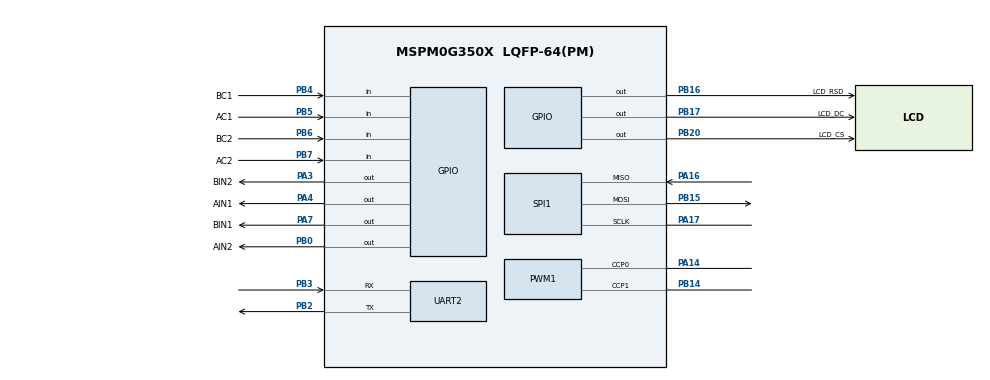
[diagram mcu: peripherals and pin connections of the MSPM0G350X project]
/**
 * @cliArgs --device "MSPM0G350X" --package "LQFP-64(PM)" --part "Default" --product "mspm0_sdk@1.30.00.03"
 * @versions {"tool":"1.19.0+3426"}
 */

/**
 * Import the modules used in this configuration.
 */
const GPIO    = scripting.addModule("/ti/driverlib/GPIO", {}, false);
const GPIO1   = GPIO.addInstance();
const GPIO2   = GPIO.addInstance();
const GPIO3   = GPIO.addInstance();
const GPIO4   = GPIO.addInstance();
const GPIO5   = GPIO.addInstance();
const GPIO6   = GPIO.addInstance();
const GPIO7   = GPIO.addInstance();
const GPIO8   = GPIO.addInstance();
const I2C     = scripting.addModule("/ti/driverlib/I2C", {}, false);
const I2C1    = I2C.addInstance();
const PWM     = scripting.addModule("/ti/driverlib/PWM", {}, false);
const PWM1    = PWM.addInstance();
const SPI     = scripting.addModule("/ti/driverlib/SPI", {}, false);
const SPI1    = SPI.addInstance();
const SYSCTL  = scripting.addModule("/ti/driverlib/SYSCTL");
const SYSTICK = scripting.addModule("/ti/driverlib/SYSTICK");
const TIMER   = scripting.addModule("/ti/driverlib/TIMER", {}, false);
const TIMER1  = TIMER.addInstance();
const TIMER2  = TIMER.addInstance();
const TIMER3  = TIMER.addInstance();
const UART    = scripting.addModule("/ti/driverlib/UART", {}, false);
const UART1   = UART.addInstance();
const UART2   = UART.addInstance();
const UART3   = UART.addInstance();

/**
 * Write custom configuration values to the imported modules.
 */
const divider7       = system.clockTree["PLL_PDIV"];
divider7.divideValue = 2;

const divider9       = system.clockTree["UDIV"];
divider9.divideValue = 2;

const multiplier2         = system.clockTree["PLL_QDIV"];
multiplier2.multiplyValue = 10;

const mux8       = system.clockTree["HSCLKMUX"];
mux8.inputSelect = "HSCLKMUX_SYSPLL0";

const pinFunction4     = system.clockTree["HFXT"];
pinFunction4.enable    = true;
pinFunction4.inputFreq = 40;

GPIO1.port                          = "PORTB";
GPIO1.$name                         = "GPIO_RGBS";
GPIO1.associatedPins.create(3);
GPIO1.associatedPins[0].assignedPin = "22";
GPIO1.associatedPins[0].$name       = "RGB_B";
GPIO1.associatedPins[1].assignedPin = "26";
GPIO1.associatedPins[1].$name       = "RGB_R";
GPIO1.associatedPins[2].assignedPin = "27";
GPIO1.associatedPins[2].$name       = "RGB_G";

const Board = scripting.addModule("/ti/driverlib/Board", {}, false);

GPIO2.$name                         = "GPIO_LEDS";
GPIO2.port                          = "PORTA";
GPIO2.associatedPins[0].assignedPin = "0";
GPIO2.associatedPins[0].$name       = "LED_0";

GPIO3.$name                              = "GPIO_KEY";
GPIO3.associatedPins.create(2);
GPIO3.associatedPins[0].$name            = "KEY_2";
GPIO3.associatedPins[0].direction        = "INPUT";
GPIO3.associatedPins[0].internalResistor = "PULL_UP";
GPIO3.associatedPins[0].assignedPort     = "PORTB";
GPIO3.associatedPins[0].assignedPin      = "23";
GPIO3.associatedPins[1].$name            = "KEY_3";
GPIO3.associatedPins[1].direction        = "INPUT";
GPIO3.associatedPins[1].internalResistor = "PULL_UP";
GPIO3.associatedPins[1].assignedPort     = "PORTB";
GPIO3.associatedPins[1].assignedPin      = "24";

GPIO4.port                          = "PORTA";
GPIO4.$name                         = "PORTA";
GPIO4.associatedPins.create(4);
GPIO4.associatedPins[0].$name       = "BEEP";
GPIO4.associatedPins[0].assignedPin = "27";
GPIO4.associatedPins[1].$name       = "AIN1";
GPIO4.associatedPins[1].pin.$assign = "PA4";
GPIO4.associatedPins[2].$name       = "BIN1";
GPIO4.associatedPins[2].pin.$assign = "PA7";
GPIO4.associatedPins[3].$name       = "BIN2";
GPIO4.associatedPins[3].pin.$assign = "PA3";

GPIO5.$name                               = "PORTB";
GPIO5.port                                = "PORTB";
GPIO5.associatedPins.create(10);
GPIO5.associatedPins[0].$name             = "B1";
GPIO5.associatedPins[0].direction         = "INPUT";
GPIO5.associatedPins[0].assignedPin       = "8";
GPIO5.associatedPins[1].direction         = "INPUT";
GPIO5.associatedPins[1].$name             = "B2";
GPIO5.associatedPins[1].assignedPin       = "9";
GPIO5.associatedPins[2].$name             = "B3";
GPIO5.associatedPins[2].direction         = "INPUT";
GPIO5.associatedPins[2].assignedPin       = "10";
GPIO5.associatedPins[3].$name             = "B4";
GPIO5.associatedPins[3].direction         = "INPUT";
GPIO5.associatedPins[3].assignedPin       = "11";
GPIO5.associatedPins[4].$name             = "B5";
GPIO5.associatedPins[4].direction         = "INPUT";
GPIO5.associatedPins[4].assignedPin       = "12";
GPIO5.associatedPins[5].direction         = "INPUT";
GPIO5.associatedPins[5].interruptEn       = true;
GPIO5.associatedPins[5].polarity          = "RISE_FALL";
GPIO5.associatedPins[5].$name             = "AC1";
GPIO5.associatedPins[5].interruptPriority = "1";
GPIO5.associatedPins[5].pin.$assign       = "PB5";
GPIO5.associatedPins[6].direction         = "INPUT";
GPIO5.associatedPins[6].interruptEn       = true;
GPIO5.associatedPins[6].polarity          = "RISE_FALL";
GPIO5.associatedPins[6].$name             = "BC1";
GPIO5.associatedPins[6].interruptPriority = "1";
GPIO5.associatedPins[6].pin.$assign       = "PB4";
GPIO5.associatedPins[7].direction         = "INPUT";
GPIO5.associatedPins[7].interruptEn       = true;
GPIO5.associatedPins[7].polarity          = "RISE_FALL";
GPIO5.associatedPins[7].$name             = "AC2";
GPIO5.associatedPins[7].interruptPriority = "1";
GPIO5.associatedPins[7].pin.$assign       = "PB7";
GPIO5.associatedPins[8].direction         = "INPUT";
GPIO5.associatedPins[8].$name             = "BC2";
GPIO5.associatedPins[8].interruptEn       = true;
GPIO5.associatedPins[8].polarity          = "RISE_FALL";
GPIO5.associatedPins[8].interruptPriority = "1";
GPIO5.associatedPins[8].pin.$assign       = "PB6";
GPIO5.associatedPins[9].$name             = "AIN2";
GPIO5.associatedPins[9].pin.$assign       = "PB0";

GPIO6.$name                         = "KEYA";
GPIO6.port                          = "PORTA";
GPIO6.portSegment                   = "Upper";
GPIO6.associatedPins[0].$name       = "S2";
GPIO6.associatedPins[0].direction   = "INPUT";
GPIO6.associatedPins[0].assignedPin = "18";

GPIO7.$name                         = "KEYB";
GPIO7.port                          = "PORTB";
GPIO7.associatedPins[0].$name       = "S3";
GPIO7.associatedPins[0].direction   = "INPUT";
GPIO7.associatedPins[0].assignedPin = "21";

GPIO8.$name                         = "GPIO_LCD";
GPIO8.associatedPins.create(3);
GPIO8.associatedPins[0].$name       = "LCD_RSD";
GPIO8.associatedPins[0].pin.$assign = "PB16";
GPIO8.associatedPins[1].$name       = "LCD_DC";
GPIO8.associatedPins[1].pin.$assign = "PB17";
GPIO8.associatedPins[2].$name       = "LCD_CS";
GPIO8.associatedPins[2].pin.$assign = "PB20";

I2C1.$name                           = "I2C_0";
I2C1.basicEnableController           = true;
I2C1.basicControllerStandardBusSpeed = "Fast";
I2C1.interruptPriority               = "0";
I2C1.intController                   = ["ARBITRATION_LOST","NACK","RXFIFO_TRIGGER","RX_DONE","TX_DONE"];
I2C1.peripheral.$assign              = "I2C0";
I2C1.sdaPinConfig.$name              = "ti_driverlib_gpio_GPIOPinGeneric11";
I2C1.sclPinConfig.$name              = "ti_driverlib_gpio_GPIOPinGeneric12";

PWM1.$name                      = "PWM_0";
PWM1.timerCount                 = 4000;
PWM1.pwmMode                    = "EDGE_ALIGN_UP";
PWM1.peripheral.$assign         = "TIMG12";
PWM1.peripheral.ccp0Pin.$assign = "PA14";
PWM1.peripheral.ccp1Pin.$assign = "PB14";
PWM1.PWM_CHANNEL_0.$name        = "ti_driverlib_pwm_PWMTimerCC0";
PWM1.PWM_CHANNEL_1.$name        = "ti_driverlib_pwm_PWMTimerCC1";
PWM1.ccp0PinConfig.$name        = "ti_driverlib_gpio_GPIOPinGeneric6";
PWM1.ccp1PinConfig.$name        = "ti_driverlib_gpio_GPIOPinGeneric7";

SPI1.$name                              = "SPI_LCD";
SPI1.targetBitRate                      = 1000000;
SPI1.frameFormat                        = "MOTO3";
SPI1.polarity                           = "1";
SPI1.phase                              = "1";
SPI1.peripheral.$assign                 = "SPI1";
SPI1.peripheral.sclkPin.$assign         = "PA17";
SPI1.peripheral.mosiPin.$assign         = "PB15";
SPI1.peripheral.misoPin.$assign         = "PA16";
SPI1.sclkPinConfig.direction            = scripting.forceWrite("OUTPUT");
SPI1.sclkPinConfig.onlyInternalResistor = scripting.forceWrite(false);
SPI1.sclkPinConfig.passedPeripheralType = scripting.forceWrite("Digital");
SPI1.sclkPinConfig.$name                = "ti_driverlib_gpio_GPIOPinGeneric8";
SPI1.mosiPinConfig.direction            = scripting.forceWrite("OUTPUT");
SPI1.mosiPinConfig.hideOutputInversion  = scripting.forceWrite(false);
SPI1.mosiPinConfig.onlyInternalResistor = scripting.forceWrite(false);
SPI1.mosiPinConfig.passedPeripheralType = scripting.forceWrite("Digital");
SPI1.mosiPinConfig.$name                = "ti_driverlib_gpio_GPIOPinGeneric9";
SPI1.misoPinConfig.onlyInternalResistor = scripting.forceWrite(false);
SPI1.misoPinConfig.passedPeripheralType = scripting.forceWrite("Digital");
SPI1.misoPinConfig.$name                = "ti_driverlib_gpio_GPIOPinGeneric10";

SYSCTL.forceDefaultClkConfig = true;
SYSCTL.clockTreeEn           = true;
SYSCTL.waitState             = "1";
SYSCTL.validateClkStatus     = true;

SYSTICK.periodEnable      = true;
SYSTICK.period            = 32000;
SYSTICK.interruptEnable   = true;
SYSTICK.interruptPriority = "0";
SYSTICK.systickEnable     = true;

TIMER1.$name              = "TIMER_0";
TIMER1.interrupts         = ["ZERO"];
TIMER1.timerMode          = "PERIODIC";
TIMER1.timerClkPrescale   = 256;
TIMER1.interruptPriority  = "3";
TIMER1.timerPeriod        = "1s";
TIMER1.timerClkDiv        = 4;
TIMER1.peripheral.$assign = "TIMG0";

TIMER2.$name              = "TIMER_1";
TIMER2.interrupts         = ["ZERO"];
TIMER2.timerMode          = "PERIODIC";
TIMER2.timerClkDiv        = 2;
TIMER2.timerClkPrescale   = 200;
TIMER2.timerPeriod        = "0.02";
TIMER2.interruptPriority  = "1";
TIMER2.peripheral.$assign = "TIMG6";

TIMER3.$name             = "TIMER_2";
TIMER3.timerClkPrescale  = 160;
TIMER3.interrupts        = ["ZERO"];
TIMER3.interruptPriority = "3";
TIMER3.timerClkDiv       = 8;
TIMER3.timerPeriod       = "1s";

UART1.$name                            = "UART_1";
UART1.enabledInterrupts                = ["RX","TX"];
UART1.targetBaudRate                   = 115200;
UART1.interruptPriority                = "1";
UART1.peripheral.$assign               = "UART1";
UART1.txPinConfig.direction            = scripting.forceWrite("OUTPUT");
UART1.txPinConfig.hideOutputInversion  = scripting.forceWrite(false);
UART1.txPinConfig.onlyInternalResistor = scripting.forceWrite(false);
UART1.txPinConfig.passedPeripheralType = scripting.forceWrite("Digital");
UART1.txPinConfig.$name                = "ti_driverlib_gpio_GPIOPinGeneric2";
UART1.rxPinConfig.hideOutputInversion  = scripting.forceWrite(false);
UART1.rxPinConfig.onlyInternalResistor = scripting.forceWrite(false);
UART1.rxPinConfig.passedPeripheralType = scripting.forceWrite("Digital");
UART1.rxPinConfig.$name                = "ti_driverlib_gpio_GPIOPinGeneric3";

UART2.$name                            = "UART_0";
UART2.targetBaudRate                   = 115200;
UART2.enabledInterrupts                = ["RX","TX"];
UART2.peripheral.$assign               = "UART3";
UART2.peripheral.rxPin.$assign         = "PB3";
UART2.peripheral.txPin.$assign         = "PB2";
UART2.txPinConfig.direction            = scripting.forceWrite("OUTPUT");
UART2.txPinConfig.hideOutputInversion  = scripting.forceWrite(false);
UART2.txPinConfig.onlyInternalResistor = scripting.forceWrite(false);
UART2.txPinConfig.passedPeripheralType = scripting.forceWrite("Digital");
UART2.txPinConfig.$name                = "ti_driverlib_gpio_GPIOPinGeneric0";
UART2.rxPinConfig.hideOutputInversion  = scripting.forceWrite(false);
UART2.rxPinConfig.onlyInternalResistor = scripting.forceWrite(false);
UART2.rxPinConfig.passedPeripheralType = scripting.forceWrite("Digital");
UART2.rxPinConfig.$name                = "ti_driverlib_gpio_GPIOPinGeneric1";

UART3.$name              = "UART_2";
UART3.enabledInterrupts  = ["RX","TX"];
UART3.peripheral.$assign = "UART2";
UART3.txPinConfig.$name  = "ti_driverlib_gpio_GPIOPinGeneric4";
UART3.rxPinConfig.$name  = "ti_driverlib_gpio_GPIOPinGeneric5";

/**
 * Pinmux solution for unlocked pins/peripherals. This ensures that minor changes to the automatic solver in a future
 * version of the tool will not impact the pinmux you originally saw.  These lines can be completely deleted in order to
 * re-solve from scratch.
 */
pinFunction4.peripheral.$suggestSolution           = "SYSCTL";
pinFunction4.peripheral.hfxInPin.$suggestSolution  = "PA5";
pinFunction4.peripheral.hfxOutPin.$suggestSolution = "PA6";
GPIO1.associatedPins[0].pin.$suggestSolution       = "PB22";
GPIO1.associatedPins[1].pin.$suggestSolution       = "PB26";
GPIO1.associatedPins[2].pin.$suggestSolution       = "PB27";
Board.peripheral.$suggestSolution                  = "DEBUGSS";
Board.peripheral.swclkPin.$suggestSolution         = "PA20";
Board.peripheral.swdioPin.$suggestSolution         = "PA19";
GPIO2.associatedPins[0].pin.$suggestSolution       = "PA0";
GPIO3.associatedPins[0].pin.$suggestSolution       = "PB23";
GPIO3.associatedPins[1].pin.$suggestSolution       = "PB24";
GPIO4.associatedPins[0].pin.$suggestSolution       = "PA27";
GPIO5.associatedPins[0].pin.$suggestSolution       = "PB8";
GPIO5.associatedPins[1].pin.$suggestSolution       = "PB9";
GPIO5.associatedPins[2].pin.$suggestSolution       = "PB10";
GPIO5.associatedPins[3].pin.$suggestSolution       = "PB11";
GPIO5.associatedPins[4].pin.$suggestSolution       = "PB12";
GPIO6.associatedPins[0].pin.$suggestSolution       = "PA18";
GPIO7.associatedPins[0].pin.$suggestSolution       = "PB21";
I2C1.peripheral.sdaPin.$suggestSolution            = "PA10";
I2C1.peripheral.sclPin.$suggestSolution            = "PA1";
TIMER3.peripheral.$suggestSolution                 = "TIMA0";
UART1.peripheral.rxPin.$suggestSolution            = "PA9";
UART1.peripheral.txPin.$suggestSolution            = "PA8";
UART3.peripheral.rxPin.$suggestSolution            = "PA22";
UART3.peripheral.txPin.$suggestSolution            = "PA21";
